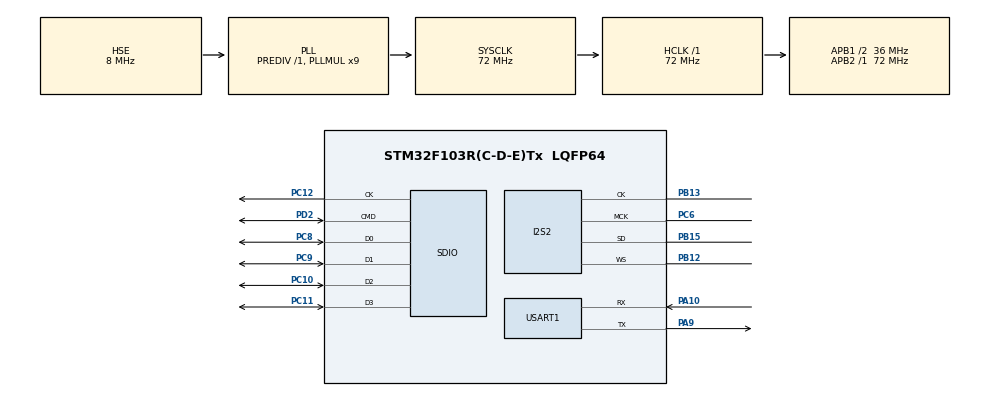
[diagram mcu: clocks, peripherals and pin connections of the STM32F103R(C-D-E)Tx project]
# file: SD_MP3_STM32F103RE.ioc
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Dma.Request0=SPI2_TX
Dma.SPI2_TX.0.Direction=DMA_MEMORY_TO_PERIPH
Dma.SPI2_TX.0.Instance=DMA1_Channel5
Dma.SPI2_TX.0.MemDataAlignment=DMA_MDATAALIGN_HALFWORD
Dma.SPI2_TX.0.MemInc=DMA_MINC_ENABLE
Dma.SPI2_TX.0.Mode=DMA_CIRCULAR
Dma.SPI2_TX.0.PeriphDataAlignment=DMA_PDATAALIGN_HALFWORD
Dma.SPI2_TX.0.PeriphInc=DMA_PINC_DISABLE
Dma.SPI2_TX.0.Priority=DMA_PRIORITY_VERY_HIGH
FATFS._CODE_PAGE=1
FATFS._STRF_ENCODE=0
FATFS._USE_STRFUNC=2
FATFS._WORD_ACCESS=0
I2S2.AudioFreq=I2S_AUDIOFREQ_44K
I2S2.ErrorAudioFreq=6.53 %
I2S2.Instance=SPI$Index
I2S2.MCLKOutput=I2S_MCLKOUTPUT_ENABLE
I2S2.RealAudioFreq=46.875 KHz
I2S2.VirtualMode=I2S_MODE_MASTER
Mcu.Family=STM32F1
Mcu.Name=STM32F103R(C-D-E)Tx
Mcu.Package=LQFP64
NVIC.DMA1_Channel5_IRQn=true\:0\:0\:false\:false\:true\:false\:true
NVIC.PriorityGroup=NVIC_PRIORITYGROUP_4
PA10.Mode=Asynchronous
PA10.Signal=USART1_RX
PA9.Mode=Asynchronous
PA9.Signal=USART1_TX
PB12.Mode=Half_Duplex_Master_TX
PB12.Signal=I2S2_WS
PB13.Mode=Half_Duplex_Master_TX
PB13.Signal=I2S2_CK
PB15.Mode=Half_Duplex_Master_TX
PB15.Signal=I2S2_SD
PC10.Mode=SD_4_bits_Wide_bus
PC10.Signal=SDIO_D2
PC11.Mode=SD_4_bits_Wide_bus
PC11.Signal=SDIO_D3
PC12.Mode=SD_4_bits_Wide_bus
PC12.Signal=SDIO_CK
PC6.Mode=Master_Clock_Activated
PC6.Signal=I2S2_MCK
PC8.Mode=SD_4_bits_Wide_bus
PC8.Signal=SDIO_D0
PC9.Mode=SD_4_bits_Wide_bus
PC9.Signal=SDIO_D1
PD0-OSC_IN.Mode=HSE-External-Oscillator
PD0-OSC_IN.Signal=RCC_OSC_IN
PD1-OSC_OUT.Mode=HSE-External-Oscillator
PD1-OSC_OUT.Signal=RCC_OSC_OUT
PD2.Mode=SD_4_bits_Wide_bus
PD2.Signal=SDIO_CMD
ProjectManager.HeapSize=0x200
ProjectManager.StackSize=0x1000
ProjectManager.TargetToolchain=MDK-ARM V5.27
RCC.AHBFreq_Value=72000000
RCC.APB1CLKDivider=RCC_HCLK_DIV2
RCC.APB1Freq_Value=36000000
RCC.APB1TimFreq_Value=72000000
RCC.APB2Freq_Value=72000000
RCC.APB2TimFreq_Value=72000000
RCC.HCLKFreq_Value=72000000
RCC.PLLMUL=RCC_PLL_MUL9
RCC.PLLSourceVirtual=RCC_PLLSOURCE_HSE
RCC.SYSCLKFreq_VALUE=72000000
RCC.SYSCLKSource=RCC_SYSCLKSOURCE_PLLCLK
RCC.USBFreq_Value=72000000
SDIO.ClockDiv=4
USART1.VirtualMode=VM_ASYNC
VP_FATFS_VS_SDIO.Mode=SDIO
VP_SYS_VS_ND.Mode=No_Debug
board=custom

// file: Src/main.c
/* USER CODE BEGIN Header */
/**
  ******************************************************************************
  * @file           : main.c
  * @brief          : Main program body
  ******************************************************************************
  * @attention
  *
  * <h2><center>&copy; Copyright (c) 2021 STMicroelectronics.
  * All rights reserved.</center></h2>
  *
  * This software component is licensed by ST under Ultimate Liberty license
  * SLA0044, the "License"; You may not use this file except in compliance with
  * the License. You may obtain a copy of the License at:
  *                             www.st.com/SLA0044
  *
  ******************************************************************************
  */
/* USER CODE END Header */

#include "main.h"
#include "dma.h"
#include "fatfs.h"
#include "i2s.h"
#include "sdio.h"
#include "usart.h"
#include "gpio.h"

void SystemClock_Config(void);

/* USER CODE BEGIN 0 */
#include "wave.h"
/* USER CODE END 0 */

int main(void)
{
  /* USER CODE BEGIN 1 */
	uint8_t res;
  /* USER CODE END 1 */

  /* MCU Configuration--------------------------------------------------------*/

  /* Reset of all peripherals, Initializes the Flash interface and the Systick. */
  HAL_Init();

  /* Configure the system clock */
  SystemClock_Config();

  /* Initialize all configured peripherals */
  MX_GPIO_Init();
  MX_DMA_Init();
  MX_I2S2_Init();
  MX_SDIO_SD_Init();
  MX_FATFS_Init();
  MX_USART1_UART_Init();
  /* USER CODE BEGIN 2 */
	//res = WM8978_Init();
	//printf("%d\r\n", res);
  if(retSD == 0){
		printf("MX_FATFS_Init OK\r\n");
		if(f_mount(&SDFatFS, (TCHAR const*)SDPath, 0) != FR_OK){
			printf("f_mount failed\r\n");
			while(1);
		}else{
			ScanWavefiles("0:/music");
		}
	}
  /* USER CODE END 2 */

  /* Infinite loop */
  while (1)
  {

  }
}

void SystemClock_Config(void)
{
  RCC_OscInitTypeDef RCC_OscInitStruct = {0};
  RCC_ClkInitTypeDef RCC_ClkInitStruct = {0};
  RCC_PeriphCLKInitTypeDef PeriphClkInit = {0};

  /** Initializes the CPU, AHB and APB busses clocks
  */
  RCC_OscInitStruct.OscillatorType = RCC_OSCILLATORTYPE_HSE;
  RCC_OscInitStruct.HSEState = RCC_HSE_ON;
  RCC_OscInitStruct.HSEPredivValue = RCC_HSE_PREDIV_DIV1;
  RCC_OscInitStruct.HSIState = RCC_HSI_ON;
  RCC_OscInitStruct.PLL.PLLState = RCC_PLL_ON;
  RCC_OscInitStruct.PLL.PLLSource = RCC_PLLSOURCE_HSE;
  RCC_OscInitStruct.PLL.PLLMUL = RCC_PLL_MUL9;
  if (HAL_RCC_OscConfig(&RCC_OscInitStruct) != HAL_OK)
  {
    Error_Handler();
  }
  /** Initializes the CPU, AHB and APB busses clocks
  */
  RCC_ClkInitStruct.ClockType = RCC_CLOCKTYPE_HCLK|RCC_CLOCKTYPE_SYSCLK
                              |RCC_CLOCKTYPE_PCLK1|RCC_CLOCKTYPE_PCLK2;
  RCC_ClkInitStruct.SYSCLKSource = RCC_SYSCLKSOURCE_PLLCLK;
  RCC_ClkInitStruct.AHBCLKDivider = RCC_SYSCLK_DIV1;
  RCC_ClkInitStruct.APB1CLKDivider = RCC_HCLK_DIV2;
  RCC_ClkInitStruct.APB2CLKDivider = RCC_HCLK_DIV1;

  if (HAL_RCC_ClockConfig(&RCC_ClkInitStruct, FLASH_LATENCY_2) != HAL_OK)
  {
    Error_Handler();
  }
  PeriphClkInit.PeriphClockSelection = RCC_PERIPHCLK_I2S2;
  PeriphClkInit.I2s2ClockSelection = RCC_I2S2CLKSOURCE_SYSCLK;
  if (HAL_RCCEx_PeriphCLKConfig(&PeriphClkInit) != HAL_OK)
  {
    Error_Handler();
  }
}

void Error_Handler(void)
{
}

/************************ (C) COPYRIGHT STMicroelectronics *****END OF FILE****/
